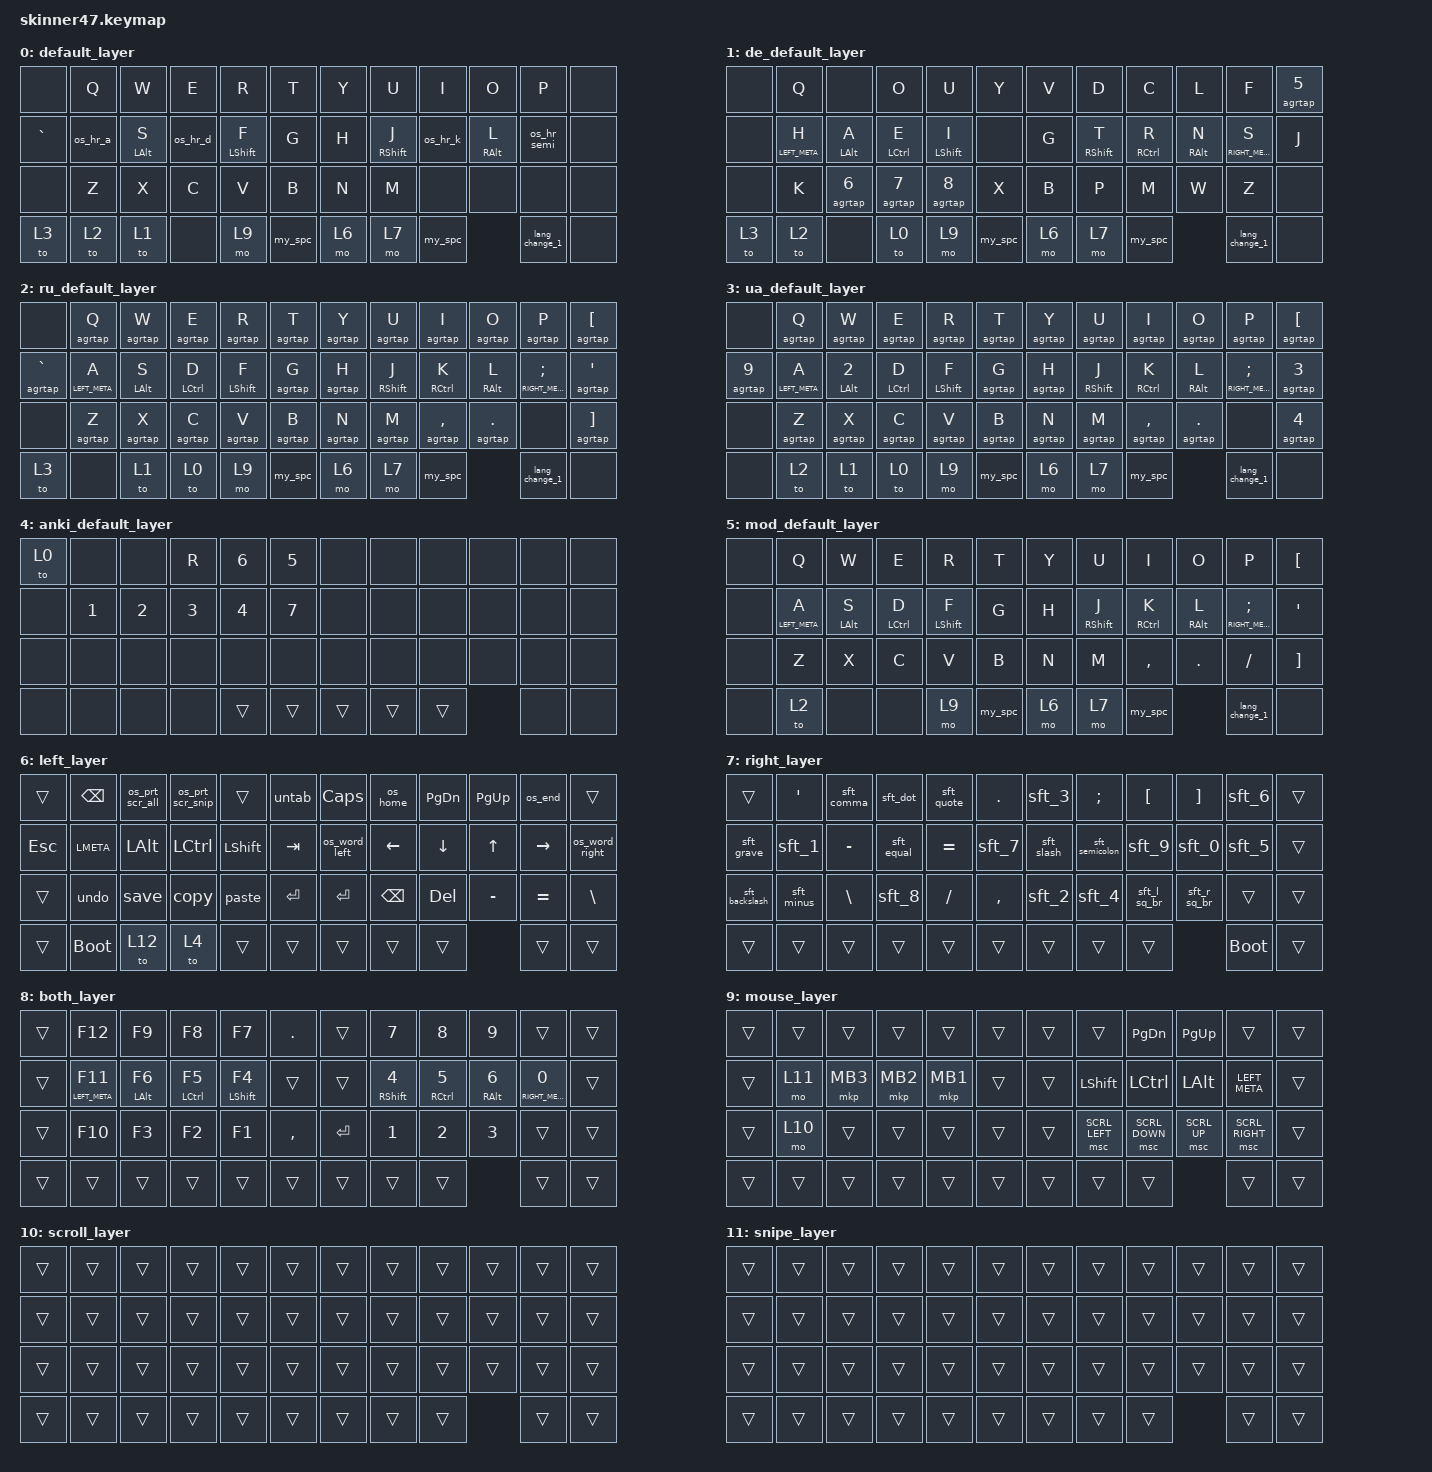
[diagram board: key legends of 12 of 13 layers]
#include <behaviors.dtsi>
#include <dt-bindings/zmk/bt.h>
#include <dt-bindings/zmk/keys.h>
#include <dt-bindings/zmk/pointing.h>

#define MY_LEFT 13 14 15 16 0 1 2 3 4 5 12 13 14 15 16 17 24 25 26 27 28 29 36 37 38 39 40 41 42 43 44
#define MY_RIGHT 19 20 21 22 6 7 8 9 10 11 18 19 20 21 22 23 30 31 32 33 34 35 43 44 45 46 40 41 42

/ {
    macros {
        copy: copy {
            compatible = "zmk,behavior-macro";
            #binding-cells = <0>;
            bindings =
                <&macro_press>,
                <&os_ctrl_cmd>,
                <&macro_tap>,
                <&kp C>,
                <&macro_release>,
                <&os_ctrl_cmd>;

            label = "COPY";
        };

        paste: paste {
            compatible = "zmk,behavior-macro";
            #binding-cells = <0>;
            bindings =
                <&macro_press>,
                <&os_ctrl_cmd>,
                <&macro_tap>,
                <&kp V>,
                <&macro_release>,
                <&os_ctrl_cmd>;

            label = "PASTE";
        };

        save: save {
            compatible = "zmk,behavior-macro";
            #binding-cells = <0>;
            bindings =
                <&macro_press>,
                <&os_ctrl_cmd>,
                <&macro_tap>,
                <&kp S>,
                <&macro_release>,
                <&os_ctrl_cmd>;

            label = "SAVE";
        };

        undo: undo {
            compatible = "zmk,behavior-macro";
            #binding-cells = <0>;
            bindings =
                <&macro_press>,
                <&os_ctrl_cmd>,
                <&macro_tap>,
                <&kp Z>,
                <&macro_release>,
                <&os_ctrl_cmd>;

            label = "UNDO";
        };

        prt_scr_all: prt_scr_all {
            compatible = "zmk,behavior-macro";
            #binding-cells = <0>;
            bindings =
                <&macro_press>,
                <&kp LEFT_META>,
                <&macro_tap>,
                <&kp PRINTSCREEN>,
                <&macro_release>,
                <&kp LEFT_META>;

            label = "PRT_SCR_ALL";
        };

        prt_scr_snip: prt_scr_snip {
            compatible = "zmk,behavior-macro";
            #binding-cells = <0>;
            bindings =
                <&macro_press>,
                <&kp LEFT_META &kp LEFT_SHIFT>,
                <&macro_tap>,
                <&kp S>,
                <&macro_release>,
                <&kp LEFT_SHIFT &kp LEFT_META>;

            label = "PRT_SCR_SNIP";
        };

        mac_prt_all: mac_prt_all {
            compatible = "zmk,behavior-macro";
            #binding-cells = <0>;
            bindings =
                <&macro_press>,
                <&kp LEFT_GUI &kp LEFT_SHIFT>,
                <&macro_tap>,
                <&kp N3>,
                <&macro_release>,
                <&kp LEFT_SHIFT &kp LEFT_GUI>;

            label = "MAC_PRT_ALL";
        };

        mac_prt_snip: mac_prt_snip {
            compatible = "zmk,behavior-macro";
            #binding-cells = <0>;
            bindings =
                <&macro_press>,
                <&kp LEFT_GUI &kp LEFT_SHIFT>,
                <&macro_tap>,
                <&kp N4>,
                <&macro_release>,
                <&kp LEFT_SHIFT &kp LEFT_GUI>;

            label = "MAC_PRT_SNIP";
        };

        mac_line_start: mac_line_start {
            compatible = "zmk,behavior-macro";
            #binding-cells = <0>;
            bindings =
                <&macro_press>,
                <&kp LEFT_GUI>,
                <&macro_tap>,
                <&kp LEFT>,
                <&macro_release>,
                <&kp LEFT_GUI>;

            label = "MAC_LINE_START";
        };

        mac_line_end: mac_line_end {
            compatible = "zmk,behavior-macro";
            #binding-cells = <0>;
            bindings =
                <&macro_press>,
                <&kp LEFT_GUI>,
                <&macro_tap>,
                <&kp RIGHT>,
                <&macro_release>,
                <&kp LEFT_GUI>;

            label = "MAC_LINE_END";
        };

        untab: untab {
            compatible = "zmk,behavior-macro";
            #binding-cells = <0>;
            bindings =
                <&macro_press>,
                <&kp LEFT_SHIFT>,
                <&macro_tap>,
                <&kp TAB>,
                <&macro_release>,
                <&kp LEFT_SHIFT>;

            label = "UNTAB";
        };

        sft_1: sft_1 {
            compatible = "zmk,behavior-macro";
            #binding-cells = <0>;
            bindings =
                <&macro_press>,
                <&kp LEFT_SHIFT>,
                <&macro_tap>,
                <&kp N1>,
                <&macro_release>,
                <&kp LEFT_SHIFT>;

            label = "!";
        };

        sft_2: sft_2 {
            compatible = "zmk,behavior-macro";
            #binding-cells = <0>;
            bindings =
                <&macro_press>,
                <&kp LEFT_SHIFT>,
                <&macro_tap>,
                <&kp N2>,
                <&macro_release>,
                <&kp LEFT_SHIFT>;

            label = "@";
        };

        sft_3: sft_3 {
            compatible = "zmk,behavior-macro";
            #binding-cells = <0>;
            bindings =
                <&macro_press>,
                <&kp LEFT_SHIFT>,
                <&macro_tap>,
                <&kp N3>,
                <&macro_release>,
                <&kp LEFT_SHIFT>;

            label = "#";
        };

        sft_4: sft_4 {
            compatible = "zmk,behavior-macro";
            #binding-cells = <0>;
            bindings =
                <&macro_press>,
                <&kp LEFT_SHIFT>,
                <&macro_tap>,
                <&kp N4>,
                <&macro_release>,
                <&kp LEFT_SHIFT>;

            label = "$";
        };

        sft_5: sft_5 {
            compatible = "zmk,behavior-macro";
            #binding-cells = <0>;
            bindings =
                <&macro_press>,
                <&kp LEFT_SHIFT>,
                <&macro_tap>,
                <&kp N5>,
                <&macro_release>,
                <&kp LEFT_SHIFT>;

            label = "%";
        };

        sft_6: sft_6 {
            compatible = "zmk,behavior-macro";
            #binding-cells = <0>;
            bindings =
                <&macro_press>,
                <&kp LEFT_SHIFT>,
                <&macro_tap>,
                <&kp N6>,
                <&macro_release>,
                <&kp LEFT_SHIFT>;

            label = "^";
        };

        sft_7: sft_7 {
            compatible = "zmk,behavior-macro";
            #binding-cells = <0>;
            bindings =
                <&macro_press>,
                <&kp LEFT_SHIFT>,
                <&macro_tap>,
                <&kp N7>,
                <&macro_release>,
                <&kp LEFT_SHIFT>;

            label = "&";
        };

        sft_8: sft_8 {
            compatible = "zmk,behavior-macro";
            #binding-cells = <0>;
            bindings =
                <&macro_press>,
                <&kp LEFT_SHIFT>,
                <&macro_tap>,
                <&kp N8>,
                <&macro_release>,
                <&kp LEFT_SHIFT>;

            label = "*";
        };

        sft_9: sft_9 {
            compatible = "zmk,behavior-macro";
            #binding-cells = <0>;
            bindings =
                <&macro_press>,
                <&kp LEFT_SHIFT>,
                <&macro_tap>,
                <&kp N9>,
                <&macro_release>,
                <&kp LEFT_SHIFT>;

            label = "(";
        };

        sft_0: sft_0 {
            compatible = "zmk,behavior-macro";
            #binding-cells = <0>;
            bindings =
                <&macro_press>,
                <&kp LEFT_SHIFT>,
                <&macro_tap>,
                <&kp N0>,
                <&macro_release>,
                <&kp LEFT_SHIFT>;

            label = ")";
        };

        sft_minus: sft_minus {
            compatible = "zmk,behavior-macro";
            #binding-cells = <0>;
            bindings =
                <&macro_press>,
                <&kp LEFT_SHIFT>,
                <&macro_tap>,
                <&kp MINUS>,
                <&macro_release>,
                <&kp LEFT_SHIFT>;

            label = "_";
        };

        sft_equal: sft_equal {
            compatible = "zmk,behavior-macro";
            #binding-cells = <0>;
            bindings =
                <&macro_press>,
                <&kp LEFT_SHIFT>,
                <&macro_tap>,
                <&kp EQUAL>,
                <&macro_release>,
                <&kp LEFT_SHIFT>;

            label = "+";
        };

        sft_backslash: sft_backslash {
            compatible = "zmk,behavior-macro";
            #binding-cells = <0>;
            bindings =
                <&macro_press>,
                <&kp LEFT_SHIFT>,
                <&macro_tap>,
                <&kp BACKSLASH>,
                <&macro_release>,
                <&kp LEFT_SHIFT>;

            label = "|";
        };

        sft_l_sq_br: sft_l_sq_br {
            compatible = "zmk,behavior-macro";
            #binding-cells = <0>;
            bindings =
                <&macro_press>,
                <&kp LEFT_SHIFT>,
                <&macro_tap>,
                <&kp LEFT_BRACKET>,
                <&macro_release>,
                <&kp LEFT_SHIFT>;

            label = "{";
        };

        sft_r_sq_br: sft_r_sq_br {
            compatible = "zmk,behavior-macro";
            #binding-cells = <0>;
            bindings =
                <&macro_press>,
                <&kp LEFT_SHIFT>,
                <&macro_tap>,
                <&kp RIGHT_BRACKET>,
                <&macro_release>,
                <&kp LEFT_SHIFT>;

            label = "}";
        };

        sft_semicolon: sft_semicolon {
            compatible = "zmk,behavior-macro";
            #binding-cells = <0>;
            bindings =
                <&macro_press>,
                <&kp LEFT_SHIFT>,
                <&macro_tap>,
                <&kp SEMICOLON>,
                <&macro_release>,
                <&kp LEFT_SHIFT>;

            label = ":";
        };

        sft_quote: sft_quote {
            compatible = "zmk,behavior-macro";
            #binding-cells = <0>;
            bindings =
                <&macro_press>,
                <&kp LEFT_SHIFT>,
                <&macro_tap>,
                <&kp SINGLE_QUOTE>,
                <&macro_release>,
                <&kp LEFT_SHIFT>;

            label = "double quote";
        };

        sft_comma: sft_comma {
            compatible = "zmk,behavior-macro";
            #binding-cells = <0>;
            bindings =
                <&macro_press>,
                <&kp LEFT_SHIFT>,
                <&macro_tap>,
                <&kp COMMA>,
                <&macro_release>,
                <&kp LEFT_SHIFT>;

            label = "open angle br";
        };

        sft_dot: sft_dot {
            compatible = "zmk,behavior-macro";
            #binding-cells = <0>;
            bindings =
                <&macro_press>,
                <&kp LEFT_SHIFT>,
                <&macro_tap>,
                <&kp DOT>,
                <&macro_release>,
                <&kp LEFT_SHIFT>;

            label = "close angle br";
        };

        sft_slash: sft_slash {
            compatible = "zmk,behavior-macro";
            #binding-cells = <0>;
            bindings =
                <&macro_press>,
                <&kp LEFT_SHIFT>,
                <&macro_tap>,
                <&kp SLASH>,
                <&macro_release>,
                <&kp LEFT_SHIFT>;

            label = "?";
        };

        sft_grave: sft_grave {
            compatible = "zmk,behavior-macro";
            #binding-cells = <0>;
            bindings =
                <&macro_press>,
                <&kp LEFT_SHIFT>,
                <&macro_tap>,
                <&kp GRAVE>,
                <&macro_release>,
                <&kp LEFT_SHIFT>;

            label = "~";
        };

        lang_change_1: lang_change_1 {
            compatible = "zmk,behavior-macro";
            #binding-cells = <0>;
            bindings =
                <&macro_press>,
                <&kp LEFT_ALT>,
                <&macro_tap>,
                <&kp LSHFT>,
                <&macro_release>,
                <&kp LALT>;

            label = "LANG_CHANGE_1";
        };

        lang_change_2: lang_change_2 {
            compatible = "zmk,behavior-macro";
            #binding-cells = <0>;
            bindings =
                <&macro_press>,
                <&kp LEFT_ALT>,
                <&macro_tap>,
                <&kp LSHFT &kp LSHFT>,
                <&macro_release>,
                <&kp LALT>;

            label = "LANG_CHANGE_2";
        };

        lang_change_3: lang_change_3 {
            compatible = "zmk,behavior-macro";
            #binding-cells = <0>;
            bindings =
                <&macro_press>,
                <&kp LEFT_ALT>,
                <&macro_tap>,
                <&kp LSHFT &kp LSHFT &kp LSHFT>,
                <&macro_release>,
                <&kp LALT>;

            label = "LANG_CHANGE_3";
        };

        mod_layer: mod_layer {
            compatible = "zmk,behavior-macro-one-param";
            wait-ms = <0>;
            tap-ms = <0>;
            #binding-cells = <1>;
            bindings =
                <&macro_press>,
                <&mo 5 &macro_param_1to1 &kp MACRO_PLACEHOLDER>,
                <&macro_pause_for_release>,
                <&macro_param_1to1>,
                <&macro_release>,
                <&kp MACRO_PLACEHOLDER &mo 5>;

            label = "mod and mod layer";
        };

        agrtap: agrtap {
            compatible = "zmk,behavior-macro-one-param";
            #binding-cells = <1>;
            wait-ms = <10>;
            bindings =
                <&macro_press>,
                <&kp RIGHT_ALT>,
                <&macro_tap>,
                <&macro_param_1to1 &kp MACRO_PLACEHOLDER>,
                <&macro_release>,
                <&kp RIGHT_ALT>;

            label = "a tap";
        };

        my_spc: my_spc {
            compatible = "zmk,behavior-macro";
            #binding-cells = <0>;
            wait-ms = <0>;
            bindings =
                <&macro_press>,
                <&kp SPACE>,
                <&macro_release>,
                <&kp SPACE>;

            label = "my space";
        };

        bt_sel_mac: bt_sel_mac {
            compatible = "zmk,behavior-macro";
            #binding-cells = <0>;
            bindings =
                <&macro_tap>,
                <&bt BT_SEL 0>,
                <&set_os 0>;
            label = "BT_SEL_MAC";
        };

        bt_sel_win: bt_sel_win {
            compatible = "zmk,behavior-macro";
            #binding-cells = <0>;
            bindings =
                <&macro_tap>,
                <&bt BT_SEL 1>,
                <&set_os 1>;
            label = "BT_SEL_WIN";
        };

        bt_sel_lin: bt_sel_lin {
            compatible = "zmk,behavior-macro";
            #binding-cells = <0>;
            bindings =
                <&macro_tap>,
                <&bt BT_SEL 2>,
                <&set_os 2>;
            label = "BT_SEL_LIN";
        };

        bt_sel_win_3: bt_sel_win_3 {
            compatible = "zmk,behavior-macro";
            #binding-cells = <0>;
            bindings =
                <&macro_tap>,
                <&bt BT_SEL 3>,
                <&set_os 1>;
            label = "BT_SEL_WIN_3";
        };

        bt_sel_win_4: bt_sel_win_4 {
            compatible = "zmk,behavior-macro";
            #binding-cells = <0>;
            bindings =
                <&macro_tap>,
                <&bt BT_SEL 4>,
                <&set_os 1>;
            label = "BT_SEL_WIN_4";
        };
    };

    combos {
        compatible = "zmk,combos";

        combo_shift_left {
            bindings = <&kp LEFT_SHIFT>;
            key-positions = <16 17>;
            layers = <0 1 2 3>;
            timeout-ms = <50>;
        };

        combo_shift_right {
            bindings = <&kp RIGHT_SHIFT>;
            key-positions = <18 19>;
            timeout-ms = <50>;
            layers = <0 1 2 3>;
        };
    };

    behaviors {
        // ------------------------------- MODIFIER + MOD LAYER + ALTGR -----------------------

        hmlal: home_row_mod_layer_alt_left {
            compatible = "zmk,behavior-hold-tap";
            label = "HML Mod AltGr";
            #binding-cells = <2>;
            flavor = "balanced";
            tapping-term-ms = <200>;
            quick-tap-ms = <200>;
            require-prior-idle-ms = <125>;
            hold-trigger-on-release;
            hold-trigger-key-positions = <MY_LEFT>;
            bindings = <&mod_layer>, <&agrtap>;
        };

        hmlar: home_row_mod_layer_alt_right {
            compatible = "zmk,behavior-hold-tap";
            label = "HMR Mod AltGr";
            #binding-cells = <2>;
            flavor = "balanced";
            tapping-term-ms = <200>;
            quick-tap-ms = <200>;
            require-prior-idle-ms = <125>;
            hold-trigger-on-release;
            hold-trigger-key-positions = <MY_RIGHT>;
            bindings = <&mod_layer>, <&agrtap>;
        };

        // ------------------------------- MODIFIER + ALTGR -----------------------

        hmal: home_row_mod_alt_left {
            compatible = "zmk,behavior-hold-tap";
            label = "HML AltGr";
            #binding-cells = <2>;
            flavor = "balanced";
            tapping-term-ms = <200>;
            quick-tap-ms = <200>;
            require-prior-idle-ms = <125>;
            hold-trigger-on-release;
            hold-trigger-key-positions = <MY_LEFT>;
            bindings = <&kp>, <&agrtap>;
        };

        hmar: home_row_mod_alt_right {
            compatible = "zmk,behavior-hold-tap";
            label = "HMR AltGr";
            #binding-cells = <2>;
            flavor = "balanced";
            tapping-term-ms = <200>;
            quick-tap-ms = <200>;
            require-prior-idle-ms = <125>;
            hold-trigger-on-release;
            hold-trigger-key-positions = <MY_RIGHT>;
            bindings = <&kp>, <&agrtap>;
        };

        // ------------------------------- MODIFIER + MOD LAYER -----------------------

        hmll: home_row_mod_layer_left {
            compatible = "zmk,behavior-hold-tap";
            label = "HML Mod";
            #binding-cells = <2>;
            flavor = "balanced";
            tapping-term-ms = <200>;
            quick-tap-ms = <200>;
            require-prior-idle-ms = <125>;
            hold-trigger-on-release;
            hold-trigger-key-positions = <MY_LEFT>;
            bindings = <&mod_layer>, <&kp>;
        };

        hmlr: home_row_mod_layer_right {
            compatible = "zmk,behavior-hold-tap";
            label = "HMR Mod";
            #binding-cells = <2>;
            flavor = "balanced";
            tapping-term-ms = <200>;
            quick-tap-ms = <200>;
            require-prior-idle-ms = <125>;
            hold-trigger-on-release;
            hold-trigger-key-positions = <MY_RIGHT>;
            bindings = <&mod_layer>, <&kp>;
        };

        // ------------------------------- MODIFIER -----------------------

        hml: home_row_mod_left {
            compatible = "zmk,behavior-hold-tap";
            label = "HML";
            #binding-cells = <2>;
            flavor = "balanced";
            tapping-term-ms = <200>;
            quick-tap-ms = <200>;
            require-prior-idle-ms = <125>;
            hold-trigger-on-release;
            hold-trigger-key-positions = <MY_LEFT>;
            bindings = <&kp>, <&kp>;
        };

        hmr: home_row_mod_right {
            compatible = "zmk,behavior-hold-tap";
            label = "HMR";
            #binding-cells = <2>;
            flavor = "balanced";
            tapping-term-ms = <200>;
            quick-tap-ms = <200>;
            require-prior-idle-ms = <125>;
            hold-trigger-on-release;
            hold-trigger-key-positions = <MY_RIGHT>;
            bindings = <&kp>, <&kp>;
        };

        set_os: set_os {
            compatible = "zmk,behavior-set-os";
            #binding-cells = <1>;
        };

        os_cmd_ctrl: os_cmd_ctrl {
            compatible = "zmk,behavior-os-switch";
            #binding-cells = <0>;
            mac-bindings = <&kp LEFT_GUI>;
            win-bindings = <&kp LEFT_CONTROL>;
            lin-bindings = <&kp LEFT_CONTROL>;
        };

        os_ctrl_cmd: os_ctrl_cmd {
            compatible = "zmk,behavior-os-switch";
            #binding-cells = <0>;
            mac-bindings = <&kp LEFT_GUI>;
            win-bindings = <&kp LEFT_CONTROL>;
            lin-bindings = <&kp LEFT_CONTROL>;
        };

        os_prt_scr_all: os_prt_scr_all {
            compatible = "zmk,behavior-os-switch";
            #binding-cells = <0>;
            mac-bindings = <&mac_prt_all>;
            win-bindings = <&prt_scr_all>;
            lin-bindings = <&prt_scr_all>;
        };

        os_prt_scr_snip: os_prt_scr_snip {
            compatible = "zmk,behavior-os-switch";
            #binding-cells = <0>;
            mac-bindings = <&mac_prt_snip>;
            win-bindings = <&prt_scr_snip>;
            lin-bindings = <&prt_scr_snip>;
        };

        os_home: os_home {
            compatible = "zmk,behavior-os-switch";
            #binding-cells = <0>;
            mac-bindings = <&mac_line_start>;
            win-bindings = <&kp HOME>;
            lin-bindings = <&kp HOME>;
        };

        os_end: os_end {
            compatible = "zmk,behavior-os-switch";
            #binding-cells = <0>;
            mac-bindings = <&mac_line_end>;
            win-bindings = <&kp END>;
            lin-bindings = <&kp END>;
        };

        os_word_left: os_word_left {
            compatible = "zmk,behavior-os-switch";
            #binding-cells = <0>;
            mac-bindings = <&kp LA(LEFT)>;
            win-bindings = <&kp LC(LEFT)>;
            lin-bindings = <&kp LC(LEFT)>;
        };

        os_word_right: os_word_right {
            compatible = "zmk,behavior-os-switch";
            #binding-cells = <0>;
            mac-bindings = <&kp LA(RIGHT)>;
            win-bindings = <&kp LC(RIGHT)>;
            lin-bindings = <&kp LC(RIGHT)>;
        };

        os_hr_a: os_hr_a {
            compatible = "zmk,behavior-os-switch";
            #binding-cells = <0>;
            mac-bindings = <&hmll LEFT_CONTROL A>;
            win-bindings = <&hmll LEFT_META A>;
            lin-bindings = <&hmll LEFT_META A>;
        };

        os_hr_d: os_hr_d {
            compatible = "zmk,behavior-os-switch";
            #binding-cells = <0>;
            mac-bindings = <&hmll LEFT_META D>;
            win-bindings = <&hmll LEFT_CONTROL D>;
            lin-bindings = <&hmll LEFT_CONTROL D>;
        };

        os_hr_k: os_hr_k {
            compatible = "zmk,behavior-os-switch";
            #binding-cells = <0>;
            mac-bindings = <&hmlr RIGHT_META K>;
            win-bindings = <&hmlr RCTRL K>;
            lin-bindings = <&hmlr RCTRL K>;
        };

        os_hr_semi: os_hr_semi {
            compatible = "zmk,behavior-os-switch";
            #binding-cells = <0>;
            mac-bindings = <&hmlr RCTRL SEMICOLON>;
            win-bindings = <&hmlr RIGHT_META SEMICOLON>;
            lin-bindings = <&hmlr RIGHT_META SEMICOLON>;
        };
    };

    keymap {
        compatible = "zmk,keymap";

        default_layer {
            bindings = <
&none      &kp Q      &kp W             &kp E     &kp R              &kp T                  &kp Y    &kp U         &kp I          &kp O              &kp P          &none
&kp GRAVE  &os_hr_a   &hmll LEFT_ALT S  &os_hr_d  &hml LEFT_SHIFT F  &kp G                  &kp H    &hmr RSHFT J  &os_hr_k       &hmlr RIGHT_ALT L  &os_hr_semi    &none
&none      &kp Z      &kp X             &kp C     &kp V              &kp B                  &kp N    &kp M         &none          &none              &none          &none
&to 3      &to 2      &to 1             &none     &mo 9              &my_spc  &mo 6  &mo 7  &my_spc                                                  &lang_change_1 &none
            >;
        };

        de_default_layer {
            bindings = <
&none  &kp Q              &none             &kp O                 &kp U              &kp Y                  &kp V    &kp D         &kp C          &kp L              &kp F                 &agrtap N5
&none  &hmll LEFT_META H  &hmll LEFT_ALT A  &hmll LEFT_CONTROL E  &hml LEFT_SHIFT I  &none                  &kp G    &hmr RSHFT T  &hmlr RCTRL R  &hmlr RIGHT_ALT N  &hmlr RIGHT_META S    &kp J
&none  &kp K              &agrtap N6        &agrtap N7            &agrtap N8         &kp X                  &kp B    &kp P         &kp M          &kp W              &kp Z                 &none
&to 3  &to 2              &none             &to 0                 &mo 9              &my_spc  &mo 6  &mo 7  &my_spc                                                  &lang_change_1        &none
            >;
        };

        ru_default_layer {
            bindings = <
&none          &agrtap Q           &agrtap W          &agrtap E       &agrtap R      &agrtap T                &agrtap Y  &agrtap U      &agrtap I       &agrtap O      &agrtap P                    &agrtap LEFT_BRACKET
&agrtap GRAVE  &hmlal LEFT_META A  &hmlal LEFT_ALT S  &hmlal LCTRL D  &hmal LSHFT F  &agrtap G                &agrtap H  &hmar RSHFT J  &hmlar RCTRL K  &hmlar RALT L  &hmlar RIGHT_META SEMICOLON  &agrtap SINGLE_QUOTE
&none          &agrtap Z           &agrtap X          &agrtap C       &agrtap V      &agrtap B                &agrtap N  &agrtap M      &agrtap COMMA   &agrtap DOT    &none                        &agrtap RIGHT_BRACKET
&to 3          &none               &to 1              &to 0           &mo 9          &my_spc    &mo 6  &mo 7  &my_spc                                                  &lang_change_1               &none
            >;
        };

        ua_default_layer {
            bindings = <
&none       &agrtap Q           &agrtap W           &agrtap E       &agrtap R      &agrtap T                &agrtap Y  &agrtap U      &agrtap I       &agrtap O      &agrtap P                    &agrtap LEFT_BRACKET
&agrtap N9  &hmlal LEFT_META A  &hmlal LEFT_ALT N2  &hmlal LCTRL D  &hmal LSHFT F  &agrtap G                &agrtap H  &hmar RSHFT J  &hmlar RCTRL K  &hmlar RALT L  &hmlar RIGHT_META SEMICOLON  &agrtap N3
&none       &agrtap Z           &agrtap X           &agrtap C       &agrtap V      &agrtap B                &agrtap N  &agrtap M      &agrtap COMMA   &agrtap DOT    &none                        &agrtap N4
&none       &to 2               &to 1               &to 0           &mo 9          &my_spc    &mo 6  &mo 7  &my_spc                                                  &lang_change_1               &none
            >;
        };

        anki_default_layer {
            bindings = <
&to 0  &none   &none   &kp R   &kp N6  &kp N5                  &none   &none  &none  &none  &none  &none
&none  &kp N1  &kp N2  &kp N3  &kp N4  &kp N7                  &none   &none  &none  &none  &none  &none
&none  &none   &none   &none   &none   &none                   &none   &none  &none  &none  &none  &none
&none  &none   &none   &none   &trans  &trans  &trans  &trans  &trans                       &none  &none
            >;
        };

        mod_default_layer {
            bindings = <
&none  &kp Q             &kp W            &kp E                &kp R              &kp T                  &kp Y    &kp U         &kp I         &kp O             &kp P                 &kp LEFT_BRACKET
&none  &hml LEFT_META A  &hml LEFT_ALT S  &hml LEFT_CONTROL D  &hml LEFT_SHIFT F  &kp G                  &kp H    &hmr RSHFT J  &hmr RCTRL K  &hmr RIGHT_ALT L  &hmr RIGHT_META SEMI  &kp SINGLE_QUOTE
&none  &kp Z             &kp X            &kp C                &kp V              &kp B                  &kp N    &kp M         &kp COMMA     &kp DOT           &kp SLASH             &kp RIGHT_BRACKET
&none  &to 2             &none            &none                &mo 9              &my_spc  &mo 6  &mo 7  &my_spc                                                &lang_change_1        &none
            >;
        };

        left_layer {
            bindings = <
&trans      &kp BACKSPACE  &os_prt_scr_all  &os_prt_scr_snip  &trans          &untab                     &kp CAPSLOCK  &os_home       &kp PAGE_DOWN  &kp PAGE_UP  &os_end    &trans
&kp ESCAPE  &kp LMETA      &kp LEFT_ALT     &kp LCTRL         &kp LEFT_SHIFT  &kp TAB                    &os_word_left &kp LEFT       &kp DOWN       &kp UP       &kp RIGHT  &os_word_right
&trans      &undo          &save            &copy             &paste          &kp ENTER                  &kp ENTER     &kp BACKSPACE  &kp DELETE     &kp MINUS    &kp EQUAL  &kp BACKSLASH
&trans      &bootloader    &to 12           &to 4             &trans          &trans     &trans  &trans  &trans                                                   &trans     &trans
            >;
        };

        right_layer {
            bindings = <
&trans          &kp SINGLE_QUOTE  &sft_comma     &sft_dot    &sft_quote  &kp DOT                    &sft_3      &kp SEMICOLON   &kp LEFT_BRACKET  &kp RIGHT_BRACKET  &sft_6       &trans
&sft_grave      &sft_1            &kp MINUS      &sft_equal  &kp EQUAL   &sft_7                     &sft_slash  &sft_semicolon  &sft_9            &sft_0             &sft_5       &trans
&sft_backslash  &sft_minus        &kp BACKSLASH  &sft_8      &kp SLASH   &kp COMMA                  &sft_2      &sft_4          &sft_l_sq_br      &sft_r_sq_br       &trans       &trans
&trans          &trans            &trans         &trans      &trans      &trans     &trans  &trans  &trans                                                           &bootloader  &trans
            >;
        };

        both_layer {
            bindings = <
&trans  &kp F12             &kp F9        &kp F8         &kp F7         &kp DOT                    &trans     &kp N7         &kp N8         &kp N9             &trans              &trans
&trans  &hml LEFT_META F11  &hml LALT F6  &hml LCTRL F5  &hml LSHFT F4  &trans                     &trans     &hmr RSHFT N4  &hmr RCTRL N5  &hmr RIGHT_ALT N6  &hmr RIGHT_META N0  &trans
&trans  &kp F10             &kp F3        &kp F2         &kp F1         &kp COMMA                  &kp ENTER  &kp N1         &kp N2         &kp N3             &trans              &trans
&trans  &trans              &trans        &trans         &trans         &trans     &trans  &trans  &trans                                                      &trans              &trans
            >;
        };

        mouse_layer {
            bindings = <
&trans  &trans  &trans    &trans    &trans    &trans                  &trans  &trans          &kp PAGE_DOWN   &kp PAGE_UP   &trans           &trans
&trans  &mo 11  &mkp MB3  &mkp MB2  &mkp MB1  &trans                  &trans  &kp LEFT_SHIFT  &kp LCTRL       &kp LEFT_ALT  &kp LEFT_META    &trans
&trans  &mo 10  &trans    &trans    &trans    &trans                  &trans  &msc SCRL_LEFT  &msc SCRL_DOWN  &msc SCRL_UP  &msc SCRL_RIGHT  &trans
&trans  &trans  &trans    &trans    &trans    &trans  &trans  &trans  &trans                                                &trans           &trans
            >;
        };

        scroll_layer {
            bindings = <
&trans  &trans  &trans  &trans  &trans  &trans                  &trans  &trans  &trans  &trans  &trans  &trans
&trans  &trans  &trans  &trans  &trans  &trans                  &trans  &trans  &trans  &trans  &trans  &trans
&trans  &trans  &trans  &trans  &trans  &trans                  &trans  &trans  &trans  &trans  &trans  &trans
&trans  &trans  &trans  &trans  &trans  &trans  &trans  &trans  &trans                          &trans  &trans
            >;
        };

        snipe_layer {
            bindings = <
&trans  &trans  &trans  &trans  &trans  &trans                  &trans  &trans  &trans  &trans  &trans  &trans
&trans  &trans  &trans  &trans  &trans  &trans                  &trans  &trans  &trans  &trans  &trans  &trans
&trans  &trans  &trans  &trans  &trans  &trans                  &trans  &trans  &trans  &trans  &trans  &trans
&trans  &trans  &trans  &trans  &trans  &trans  &trans  &trans  &trans                          &trans  &trans
            >;
        };

        bluetooth_layer {
            bindings = <
&to 0          &none          &none          &none          &bt BT_CLR     &bt BT_CLR_ALL                &none  &none  &none  &none  &none  &none
&bt_sel_win_4  &bt_sel_win_3  &bt_sel_lin    &bt_sel_win    &bt_sel_mac    &none                         &none  &none  &none  &none  &none  &none
&bt BT_DISC 4  &bt BT_DISC 3  &bt BT_DISC 2  &bt BT_DISC 1  &bt BT_DISC 0  &none                         &none  &none  &none  &none  &none  &none
&sys_reset     &none          &none          &none          &none          &none           &none  &none  &none                       &none  &none
            >;
        };
    };

    conditional_layers {
        compatible = "zmk,conditional-layers";

        tri_layer {
            if-layers = <6 7>;
            then-layer = <8>;
        };
    };
};
